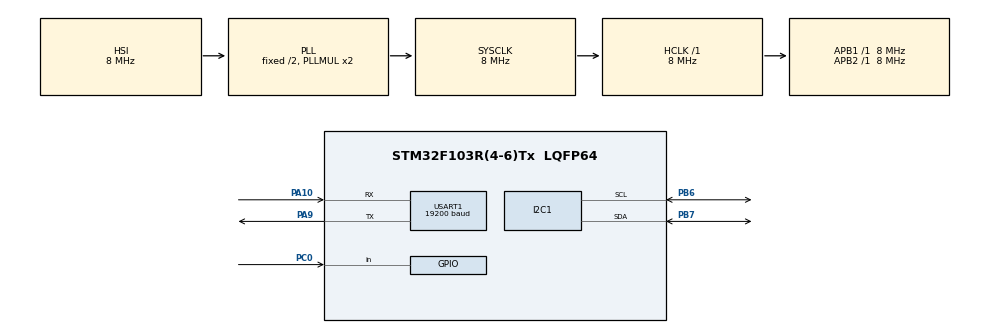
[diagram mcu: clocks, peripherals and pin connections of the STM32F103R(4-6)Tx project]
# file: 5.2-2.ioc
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Mcu.Family=STM32F1
Mcu.Name=STM32F103R(4-6)Tx
Mcu.Package=LQFP64
NVIC.I2C1_EV_IRQn=true\:0\:0\:false\:false\:true\:true\:true
NVIC.PriorityGroup=NVIC_PRIORITYGROUP_4
PA10.Mode=Asynchronous
PA10.Signal=USART1_RX
PA9.Mode=Asynchronous
PA9.Signal=USART1_TX
PB6.Mode=I2C
PB6.Signal=I2C1_SCL
PB7.Mode=I2C
PB7.Signal=I2C1_SDA
PC0.Signal=GPIO_Input
ProjectManager.HeapSize=0x200
ProjectManager.StackSize=0x400
ProjectManager.TargetToolchain=STM32CubeIDE
RCC.AHBFreq_Value=8000000
RCC.APB1Freq_Value=8000000
RCC.APB1TimFreq_Value=8000000
RCC.APB2Freq_Value=8000000
RCC.APB2TimFreq_Value=8000000
RCC.HCLKFreq_Value=8000000
RCC.SYSCLKFreq_VALUE=8000000
RCC.SYSCLKSource=RCC_SYSCLKSOURCE_PLLCLK
RCC.USBFreq_Value=8000000
USART1.BaudRate=19200
USART1.VirtualMode=VM_ASYNC
VP_SYS_VS_ND.Mode=No_Debug
board=custom

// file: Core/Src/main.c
/* USER CODE BEGIN Header */
/**
  ******************************************************************************
  * @file           : main.c
  * @brief          : Main program body
  ******************************************************************************
  * @attention
  *
  * <h2><center>&copy; Copyright (c) 2020 STMicroelectronics.
  * All rights reserved.</center></h2>
  *
  * This software component is licensed by ST under BSD 3-Clause license,
  * the "License"; You may not use this file except in compliance with the
  * License. You may obtain a copy of the License at:
  *                        opensource.org/licenses/BSD-3-Clause
  *
  ******************************************************************************
  */
/* USER CODE END Header */
#include "main.h"

/* USER CODE BEGIN PTD */
#define ADDR_AT24C02_Write 0xA0
#define ADDR_AT24C02_Read 0xA1
/* USER CODE END PTD */

I2C_HandleTypeDef hi2c1;

UART_HandleTypeDef huart1;

/* USER CODE BEGIN PV */
uint8_t I2C_Buffer_Write[8]={0x12,0x23,0x34,0x45,0x56,0x67,0x78,0x89};
uint8_t I2C_Buffer_Read[8];

/* USER CODE END PV */

void SystemClock_Config(void);
static void MX_GPIO_Init(void);
static void MX_I2C1_Init(void);
static void MX_USART1_UART_Init(void);

int main(void)
{

  /* MCU Configuration--------------------------------------------------------*/

  /* Reset of all peripherals, Initializes the Flash interface and the Systick. */
  HAL_Init();

  /* Configure the system clock */
  SystemClock_Config();

  /* Initialize all configured peripherals */
  MX_GPIO_Init();
  MX_I2C1_Init();
  MX_USART1_UART_Init();
  /* USER CODE BEGIN 2 */
  HAL_Delay(100);
  if(HAL_I2C_Mem_Write(&hi2c1, 0xa0, 0, I2C_MEMADD_SIZE_8BIT,I2C_Buffer_Write,8, 1000)==HAL_OK)
  {
	  HAL_UART_Transmit(&huart1,&"OK",3,10);
  }
  else
  {
	  HAL_UART_Transmit(&huart1,&"ERR",4,10);
  }
  //HAL_Delay(20);
  //HAL_I2C_Mem_Read(&hi2c1, 0xa1, 0, I2C_MEMADD_SIZE_8BIT,I2C_Buffer_Read,8, 1000);
  //HAL_Delay(20);
  //HAL_UART_Transmit(&huart1,I2C_Buffer_Read,8,100);
  /* USER CODE END 2 */

  /* Infinite loop */
  while (1)
  {

  }
}

void SystemClock_Config(void)
{
  RCC_OscInitTypeDef RCC_OscInitStruct = {0};
  RCC_ClkInitTypeDef RCC_ClkInitStruct = {0};

  /** Initializes the RCC Oscillators according to the specified parameters
  * in the RCC_OscInitTypeDef structure.
  */
  RCC_OscInitStruct.OscillatorType = RCC_OSCILLATORTYPE_HSI;
  RCC_OscInitStruct.HSIState = RCC_HSI_ON;
  RCC_OscInitStruct.HSICalibrationValue = RCC_HSICALIBRATION_DEFAULT;
  RCC_OscInitStruct.PLL.PLLState = RCC_PLL_ON;
  RCC_OscInitStruct.PLL.PLLSource = RCC_PLLSOURCE_HSI_DIV2;
  RCC_OscInitStruct.PLL.PLLMUL = RCC_PLL_MUL2;
  if (HAL_RCC_OscConfig(&RCC_OscInitStruct) != HAL_OK)
  {
    Error_Handler();
  }
  /** Initializes the CPU, AHB and APB buses clocks
  */
  RCC_ClkInitStruct.ClockType = RCC_CLOCKTYPE_HCLK|RCC_CLOCKTYPE_SYSCLK
                              |RCC_CLOCKTYPE_PCLK1|RCC_CLOCKTYPE_PCLK2;
  RCC_ClkInitStruct.SYSCLKSource = RCC_SYSCLKSOURCE_PLLCLK;
  RCC_ClkInitStruct.AHBCLKDivider = RCC_SYSCLK_DIV1;
  RCC_ClkInitStruct.APB1CLKDivider = RCC_HCLK_DIV1;
  RCC_ClkInitStruct.APB2CLKDivider = RCC_HCLK_DIV1;

  if (HAL_RCC_ClockConfig(&RCC_ClkInitStruct, FLASH_LATENCY_0) != HAL_OK)
  {
    Error_Handler();
  }
}

static void MX_I2C1_Init(void)
{

  hi2c1.Instance = I2C1;
  hi2c1.Init.ClockSpeed = 100000;
  hi2c1.Init.DutyCycle = I2C_DUTYCYCLE_2;
  hi2c1.Init.OwnAddress1 = 0;
  hi2c1.Init.AddressingMode = I2C_ADDRESSINGMODE_7BIT;
  hi2c1.Init.DualAddressMode = I2C_DUALADDRESS_DISABLE;
  hi2c1.Init.OwnAddress2 = 0;
  hi2c1.Init.GeneralCallMode = I2C_GENERALCALL_DISABLE;
  hi2c1.Init.NoStretchMode = I2C_NOSTRETCH_DISABLE;
  if (HAL_I2C_Init(&hi2c1) != HAL_OK)
  {
    Error_Handler();
  }

}

static void MX_USART1_UART_Init(void)
{

  huart1.Instance = USART1;
  huart1.Init.BaudRate = 19200;
  huart1.Init.WordLength = UART_WORDLENGTH_8B;
  huart1.Init.StopBits = UART_STOPBITS_1;
  huart1.Init.Parity = UART_PARITY_NONE;
  huart1.Init.Mode = UART_MODE_TX_RX;
  huart1.Init.HwFlowCtl = UART_HWCONTROL_NONE;
  huart1.Init.OverSampling = UART_OVERSAMPLING_16;
  if (HAL_UART_Init(&huart1) != HAL_OK)
  {
    Error_Handler();
  }

}

static void MX_GPIO_Init(void)
{
  GPIO_InitTypeDef GPIO_InitStruct = {0};

  /* GPIO Ports Clock Enable */
  __HAL_RCC_GPIOC_CLK_ENABLE();
  __HAL_RCC_GPIOA_CLK_ENABLE();
  __HAL_RCC_GPIOB_CLK_ENABLE();

  /*Configure GPIO pin : PC0 */
  GPIO_InitStruct.Pin = GPIO_PIN_0;
  GPIO_InitStruct.Mode = GPIO_MODE_INPUT;
  GPIO_InitStruct.Pull = GPIO_NOPULL;
  HAL_GPIO_Init(GPIOC, &GPIO_InitStruct);

}

void Error_Handler(void)
{
}

/************************ (C) COPYRIGHT STMicroelectronics *****END OF FILE****/
